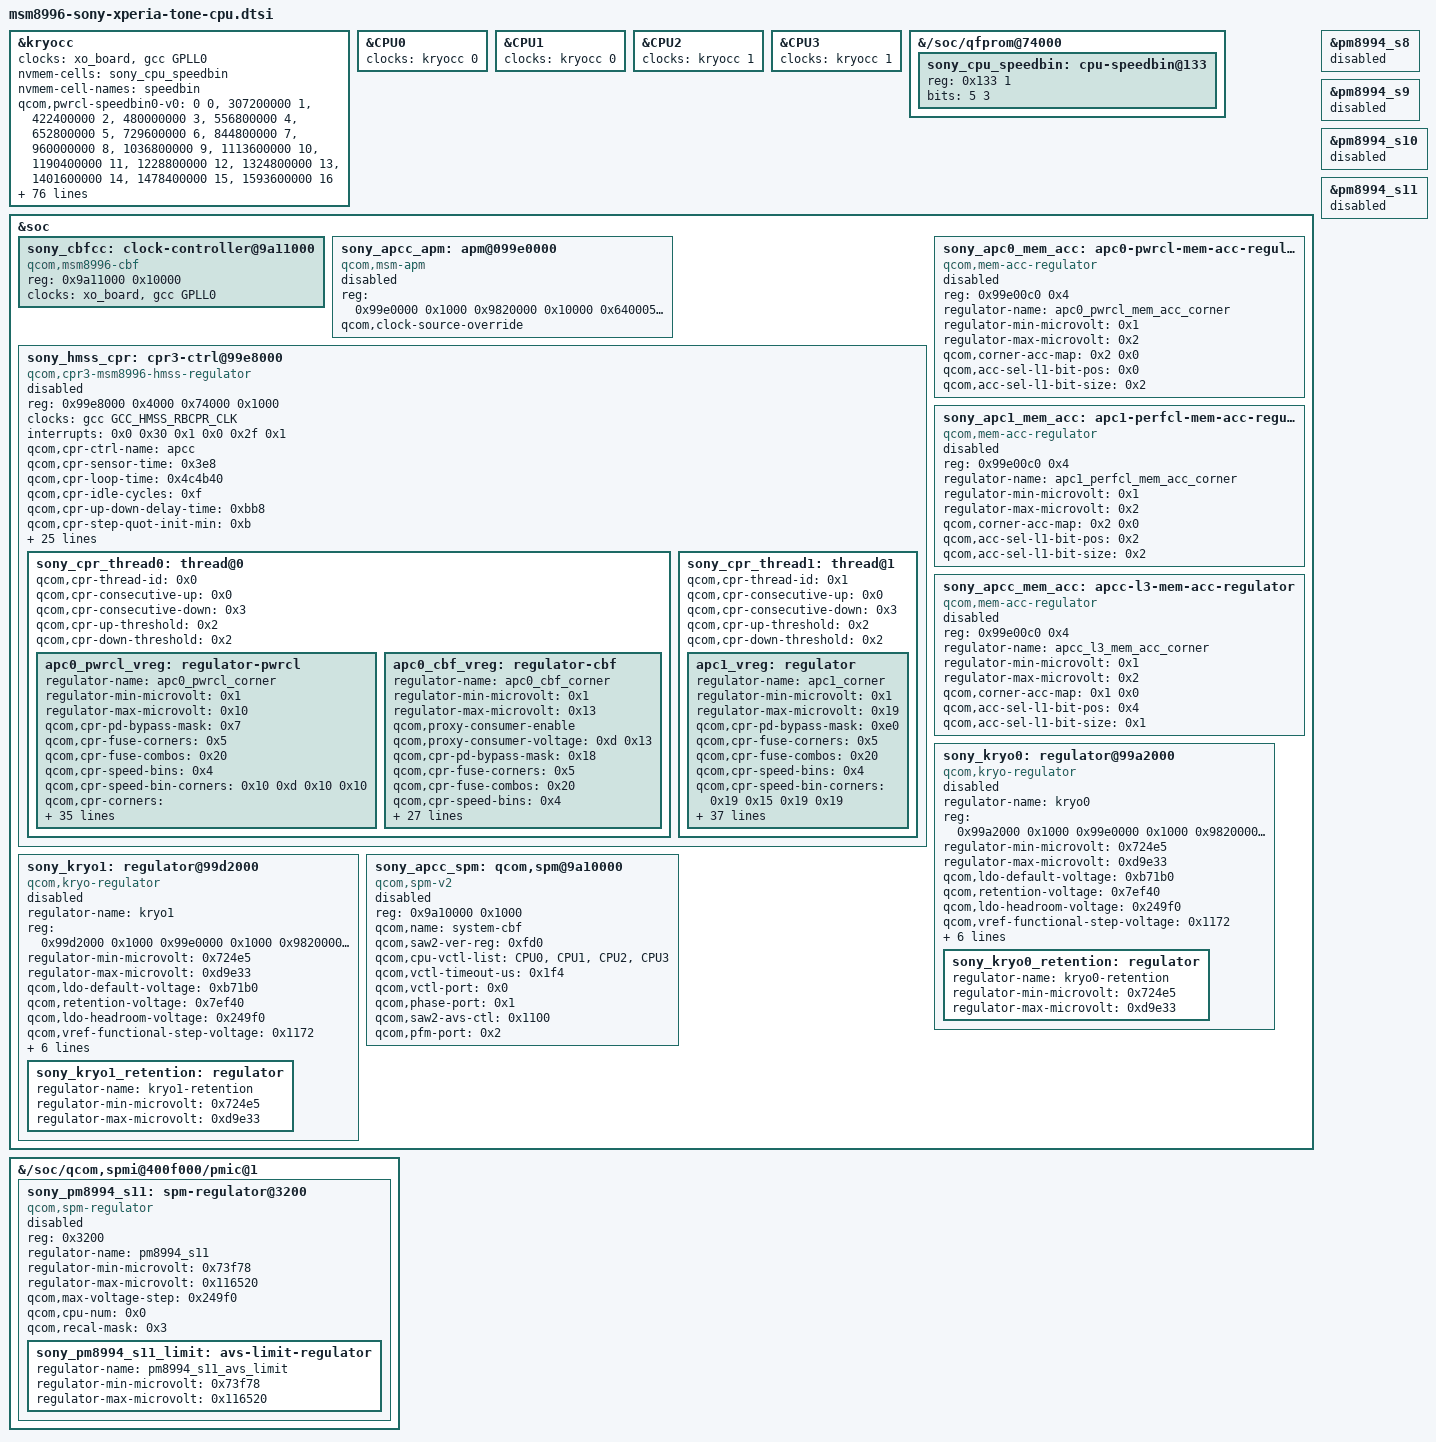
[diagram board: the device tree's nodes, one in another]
// SPDX-License-Identifier: GPL-2.0-only
/*
 * Copyright (c) 2014-2018, The Linux Foundation. All rights reserved.
 *
 * CPU/CBF data from the FINAL flattened Sony Dora v3.1/PMI8994 DT at
 * 0c295b15b6d0fb59a64e13b9e0ef2070818ef2a1, including all overrides.
 * APCC/CBF providers only observe firmware rates. All voltage controllers
 * below remain DISABLED: ACD/CPR transitions and RPM corner voting have not
 * been validated. Do not enable cpufreq, cpuidle or remove maxcpus=2 here.
 */

&kryocc {
	/* Sony sys_apcsaux_clk is GPLL0 main output divided by two. */
	clocks = <&xo_board>, <&gcc GPLL0>;
	clock-names = "xo", "aux";
	nvmem-cells = <&sony_cpu_speedbin>;
	nvmem-cell-names = "speedbin";
	qcom,pwrcl-speedbin0-v0 =
		<0 0>,
		<307200000 1>,
		<422400000 2>,
		<480000000 3>,
		<556800000 4>,
		<652800000 5>,
		<729600000 6>,
		<844800000 7>,
		<960000000 8>,
		<1036800000 9>,
		<1113600000 10>,
		<1190400000 11>,
		<1228800000 12>,
		<1324800000 13>,
		<1401600000 14>,
		<1478400000 15>,
		<1593600000 16>;
	qcom,perfcl-speedbin0-v0 =
		<0 0>,
		<307200000 1>,
		<403200000 2>,
		<480000000 3>,
		<556800000 4>,
		<652800000 5>,
		<729600000 6>,
		<806400000 7>,
		<883200000 8>,
		<940800000 9>,
		<1036800000 10>,
		<1113600000 11>,
		<1190400000 12>,
		<1248000000 13>,
		<1324800000 14>,
		<1401600000 15>,
		<1478400000 16>,
		<1555200000 17>,
		<1632000000 18>,
		<1708800000 19>,
		<1785600000 20>,
		<1824000000 21>,
		<1920000000 22>,
		<1996800000 23>,
		<2073600000 24>,
		<2150400000 25>;
	qcom,cbf-speedbin0-v0 =
		<0 0>,
		<307200000 1>,
		<384000000 2>,
		<460800000 3>,
		<537600000 4>,
		<595200000 5>,
		<672000000 6>,
		<748800000 7>,
		<825600000 8>,
		<902400000 9>,
		<979200000 10>,
		<1056000000 11>,
		<1132800000 12>,
		<1190400000 13>,
		<1228800000 14>,
		<1305600000 15>,
		<1382400000 16>,
		<1459200000 17>,
		<1536000000 18>,
		<1593600000 19>;
	qcom,pwrcl-speedbin1-v0 =
		<0 0>,
		<307200000 1>,
		<422400000 2>,
		<480000000 3>,
		<556800000 4>,
		<652800000 5>,
		<729600000 6>,
		<844800000 7>,
		<960000000 8>,
		<1036800000 9>,
		<1113600000 10>,
		<1190400000 11>,
		<1228800000 12>,
		<1363200000 13>;
	qcom,pwrcl-speedbin2-v0 =
		<0 0>,
		<307200000 1>,
		<422400000 2>,
		<480000000 3>,
		<556800000 4>,
		<652800000 5>,
		<729600000 6>,
		<844800000 7>,
		<960000000 8>,
		<1036800000 9>,
		<1113600000 10>,
		<1190400000 11>,
		<1228800000 12>,
		<1324800000 13>,
		<1401600000 14>,
		<1497600000 15>;
	qcom,pwrcl-speedbin3-v0 =
		<0 0>,
		<307200000 1>,
		<422400000 2>,
		<480000000 3>,
		<556800000 4>,
		<652800000 5>,
		<729600000 6>,
		<844800000 7>,
		<960000000 8>,
		<1036800000 9>,
		<1113600000 10>,
		<1190400000 11>,
		<1228800000 12>,
		<1324800000 13>,
		<1401600000 14>,
		<1478400000 15>,
		<1593600000 16>;
	qcom,perfcl-speedbin1-v0 =
		<0 0>,
		<307200000 1>,
		<403200000 2>,
		<480000000 3>,
		<556800000 4>,
		<652800000 5>,
		<729600000 6>,
		<806400000 7>,
		<883200000 8>,
		<940800000 9>,
		<1036800000 10>,
		<1113600000 11>,
		<1190400000 12>,
		<1248000000 13>,
		<1324800000 14>,
		<1401600000 15>,
		<1478400000 16>,
		<1555200000 17>,
		<1632000000 18>,
		<1708800000 19>,
		<1785600000 20>,
		<1804800000 21>;
	qcom,perfcl-speedbin2-v0 =
		<0 0>,
		<307200000 1>,
		<403200000 2>,
		<480000000 3>,
		<556800000 4>,
		<652800000 5>,
		<729600000 6>,
		<806400000 7>,
		<883200000 8>,
		<940800000 9>,
		<1036800000 10>,
		<1113600000 11>,
		<1190400000 12>,
		<1248000000 13>,
		<1324800000 14>,
		<1401600000 15>,
		<1478400000 16>,
		<1555200000 17>,
		<1632000000 18>,
		<1708800000 19>,
		<1785600000 20>,
		<1804800000 21>,
		<1900800000 22>;
	qcom,perfcl-speedbin3-v0 =
		<0 0>,
		<307200000 1>,
		<403200000 2>,
		<480000000 3>,
		<556800000 4>,
		<652800000 5>,
		<729600000 6>,
		<806400000 7>,
		<883200000 8>,
		<940800000 9>,
		<1036800000 10>,
		<1113600000 11>,
		<1190400000 12>,
		<1248000000 13>,
		<1324800000 14>,
		<1401600000 15>,
		<1478400000 16>,
		<1555200000 17>,
		<1632000000 18>,
		<1708800000 19>,
		<1785600000 20>,
		<1804800000 21>;
	qcom,cbf-speedbin1-v0 =
		<0 0>,
		<307200000 1>,
		<384000000 2>,
		<460800000 3>,
		<537600000 4>,
		<595200000 5>,
		<672000000 6>,
		<748800000 7>,
		<825600000 8>,
		<902400000 9>,
		<979200000 10>,
		<1056000000 11>,
		<1132800000 12>,
		<1190400000 13>,
		<1228800000 14>,
		<1305600000 15>;
	qcom,cbf-speedbin2-v0 =
		<0 0>,
		<307200000 1>,
		<384000000 2>,
		<460800000 3>,
		<537600000 4>,
		<595200000 5>,
		<672000000 6>,
		<748800000 7>,
		<825600000 8>,
		<902400000 9>,
		<979200000 10>,
		<1056000000 11>,
		<1132800000 12>,
		<1190400000 13>,
		<1228800000 14>,
		<1305600000 15>;
	qcom,cbf-speedbin3-v0 =
		<0 0>,
		<307200000 1>,
		<384000000 2>,
		<460800000 3>,
		<537600000 4>,
		<595200000 5>,
		<672000000 6>,
		<748800000 7>,
		<825600000 8>,
		<902400000 9>,
		<979200000 10>,
		<1056000000 11>,
		<1132800000 12>,
		<1190400000 13>,
		<1228800000 14>,
		<1305600000 15>,
		<1382400000 16>,
		<1459200000 17>,
		<1536000000 18>,
		<1593600000 19>;
};

&CPU0 { clocks = <&kryocc 0>; };
&CPU1 { clocks = <&kryocc 0>; };
&CPU2 { clocks = <&kryocc 1>; };
&CPU3 { clocks = <&kryocc 1>; };

&{/soc/qfprom@74000} {
	/* NVMEM bit offsets are byte-relative (0..7). Sony EFUSE[31:29]. */
	sony_cpu_speedbin: cpu-speedbin@133 {
		reg = <0x133 1>;
		bits = <5 3>;
	};
};

&soc {
	sony_cbfcc: clock-controller@9a11000 {
		compatible = "qcom,msm8996-cbf";
		reg = <0x9a11000 0x10000>;
		#clock-cells = <1>;
		clocks = <&xo_board>, <&gcc GPLL0>;
		clock-names = "xo", "aux";
	};
	sony_apcc_apm: apm@099e0000 {
		status = "disabled";
		compatible = "qcom,msm-apm";
		reg = <0x99e0000 0x1000 0x9820000 0x10000 0x6400050 0x8
			0x6480050 0x8 0x9981068 0x8 0x9991068 0x8
			0x99b1068 0x8 0x99c1068 0x8 0x99a1068 0x8
			0x99d1068 0x8>;
		reg-names = "pm-apcc-glb", "apcs-csr", "apc0-pll-ctl", "apc1-pll-ctl", "apc0-cpu0-spm", "apc0-cpu1-spm", "apc1-cpu0-spm", "apc1-cpu1-spm", "apc0-l2-spm", "apc1-l2-spm";
		qcom,clock-source-override;
	};
	sony_hmss_cpr: cpr3-ctrl@99e8000 {
		status = "disabled";
		compatible = "qcom,cpr3-msm8996-hmss-regulator";
		reg = <0x99e8000 0x4000 0x74000 0x1000>;
		reg-names = "cpr_ctrl", "fuse_base";
		clocks = <&gcc GCC_HMSS_RBCPR_CLK>;
		clock-names = "core_clk";
		interrupts = <0x0 0x30 0x1 0x0 0x2f 0x1>;
		interrupt-names = "cpr", "ceiling";
		qcom,cpr-ctrl-name = "apcc";
		qcom,cpr-sensor-time = <0x3e8>;
		qcom,cpr-loop-time = <0x4c4b40>;
		qcom,cpr-idle-cycles = <0xf>;
		qcom,cpr-up-down-delay-time = <0xbb8>;
		qcom,cpr-step-quot-init-min = <0xb>;
		qcom,cpr-step-quot-init-max = <0xd>;
		qcom,cpr-count-mode = <0x0>;
		qcom,cpr-count-repeat = <0x19>;
		qcom,apm-ctrl = <&sony_apcc_apm>;
		qcom,apm-threshold-voltage = <0xcf850>;
		qcom,apm-hysteresis-voltage = <0x1388>;
		qcom,system-supply-max-voltage = <0xf7cd8>;
		qcom,mem-acc-supply-threshold-voltage = <0xaae60>;
		qcom,mem-acc-supply-corner-map = <0x1 0x2>;
		vdd-supply = <&sony_pm8994_s11>;
		qcom,voltage-step = <0x1388>;
		vdd-limit-supply = <&sony_pm8994_s11_limit>;
		mem-acc-thread0-supply = <&sony_apc0_mem_acc>;
		mem-acc-thread1-supply = <&sony_apc1_mem_acc>;
		mem-acc-supply = <&sony_apcc_mem_acc>;
		vdd-thread0-ldo-supply = <&sony_kryo0>;
		vdd-thread1-ldo-supply = <&sony_kryo1>;
		vdd-thread0-ldo-ret-supply = <&sony_kryo0_retention>;
		vdd-thread1-ldo-ret-supply = <&sony_kryo1_retention>;
		proxy-supply = <&apc0_cbf_vreg>;
		qcom,cpr-enable;
		qcom,cpr-clock-throttling = <0x20>;
		qcom,cpr-aging-ref-voltage = <0xdcf28>;
		sony_cpr_thread0: thread@0 {
			qcom,cpr-thread-id = <0x0>;
			qcom,cpr-consecutive-up = <0x0>;
			qcom,cpr-consecutive-down = <0x3>;
			qcom,cpr-up-threshold = <0x2>;
			qcom,cpr-down-threshold = <0x2>;
			apc0_pwrcl_vreg: regulator-pwrcl {
				regulator-name = "apc0_pwrcl_corner";
				regulator-min-microvolt = <0x1>;
				regulator-max-microvolt = <0x10>;
				qcom,cpr-pd-bypass-mask = <0x7>;
				qcom,cpr-fuse-corners = <0x5>;
				qcom,cpr-fuse-combos = <0x20>;
				qcom,cpr-speed-bins = <0x4>;
				qcom,cpr-speed-bin-corners = <0x10 0xd 0x10 0x10>;
				qcom,cpr-corners = <0x10 0x10 0x10 0x10 0x10 0x10
					0x10 0x10 0xd 0xd 0xd 0xd
					0xd 0xd 0xd 0xd 0x10 0x10
					0x10 0x10 0x10 0x10 0x10 0x10
					0x10 0x10 0x10 0x10 0x10 0x10
					0x10 0x10>;
				qcom,ldo-min-headroom-voltage = <0x249f0>;
				qcom,ldo-max-headroom-voltage = <0x72bf0>;
				qcom,ldo-max-voltage = <0xd9490>;
				qcom,uses-mem-acc;
				qcom,cpr-corner-fmax-map = <0x1 0x2 0x7 0xc 0x10 0x1
					0x2 0x7 0xc 0xd 0x1 0x2
					0x7 0xc 0x10 0x1 0x2 0x7
					0xc 0x10>;
				qcom,cpr-voltage-ceiling = <0xa3930 0xa3930 0xb5e28 0xb5e28 0xb5e28 0xb5e28
					0xb5e28 0xdcf28 0xdcf28 0xdcf28 0xdcf28 0xdcf28
					0x116520 0x116520 0x116520 0x116520 0xa3930 0xa3930
					0xb5e28 0xb5e28 0xb5e28 0xb5e28 0xb5e28 0xdcf28
					0xdcf28 0xdcf28 0xdcf28 0xdcf28 0x116520 0xa3930
					0xa3930 0xb5e28 0xb5e28 0xb5e28 0xb5e28 0xb5e28
					0xdcf28 0xdcf28 0xdcf28 0xdcf28 0xdcf28 0x116520
					0x116520 0x116520 0x116520 0xa3930 0xa3930 0xb5e28
					0xb5e28 0xb5e28 0xb5e28 0xb5e28 0xdcf28 0xdcf28
					0xdcf28 0xdcf28 0xdcf28 0x116520 0x116520 0x116520
					0x116520>;
				qcom,cpr-voltage-floor = <0x98968 0x98968 0x98968 0x98968 0x98968 0x98968
					0x98968 0x98968 0x98968 0x98968 0x98968 0x98968
					0x98968 0x98968 0x98968 0x98968 0x98968 0x98968
					0x98968 0x98968 0x98968 0x98968 0x98968 0x98968
					0x98968 0x98968 0x98968 0x98968 0x98968 0x98968
					0x98968 0x98968 0x98968 0x98968 0x98968 0x98968
					0x98968 0x98968 0x98968 0x98968 0x98968 0x98968
					0x98968 0x98968 0x98968 0x98968 0x98968 0x98968
					0x98968 0x98968 0x98968 0x98968 0x98968 0x98968
					0x98968 0x98968 0x98968 0x98968 0x98968 0x98968
					0x98968 0x98968 0x98968 0x98968 0x98968 0x98968
					0x98968 0x98968 0x98968 0x98968 0x98968 0x98968
					0x98968 0x98968 0x98968 0x98968 0x98968 0x98968
					0x98968 0x98968 0x98968 0x98968 0x98968 0x98968
					0x98968 0x98968 0x98968 0x98968 0x98968 0x98968
					0x98968 0x98968 0x98968 0x98968 0x98968 0x98968
					0x72bf0 0x72bf0 0x72bf0 0x72bf0 0x72bf0 0x72bf0
					0x72bf0 0x72bf0 0x72bf0 0x72bf0 0x72bf0 0x72bf0
					0x72bf0 0x72bf0 0x72bf0 0x72bf0 0x72bf0 0x72bf0
					0x72bf0 0x72bf0 0x72bf0 0x72bf0 0x72bf0 0x72bf0
					0x72bf0 0x72bf0 0x72bf0 0x72bf0 0x72bf0 0x72bf0
					0x72bf0 0x72bf0 0x98968 0x98968 0x98968 0x98968
					0x98968 0x98968 0x98968 0x98968 0x98968 0x98968
					0x98968 0x98968 0x98968 0x98968 0x98968 0x98968
					0x98968 0x98968 0x98968 0x98968 0x98968 0x98968
					0x98968 0x98968 0x98968 0x98968 0x98968 0x98968
					0x98968 0x98968 0x98968 0x98968 0x98968 0x98968
					0x98968 0x98968 0x98968 0x98968 0x98968 0x98968
					0x98968 0x98968 0x98968 0x98968 0x98968 0x98968
					0x98968 0x98968 0x98968 0x98968 0x98968 0x98968
					0x98968 0x98968 0x98968 0x98968 0x98968 0x98968
					0x98968 0x98968 0x98968 0x98968 0x98968 0x98968
					0x98968 0x98968 0x98968 0x98968 0x98968 0x98968
					0x98968 0x98968 0x98968 0x98968 0x98968 0x98968
					0x98968 0x98968 0x72bf0 0x72bf0 0x72bf0 0x72bf0
					0x72bf0 0x72bf0 0x72bf0 0x72bf0 0x72bf0 0x72bf0
					0x72bf0 0x72bf0 0x72bf0 0x72bf0 0x72bf0 0x72bf0
					0x72bf0 0x72bf0 0x72bf0 0x72bf0 0x72bf0 0x72bf0
					0x72bf0 0x72bf0 0x72bf0 0x72bf0 0x98968 0x98968
					0x98968 0x98968 0x98968 0x98968 0x98968 0x98968
					0x98968 0x98968 0x98968 0x98968 0x98968 0x98968
					0x98968 0x98968 0x98968 0x98968 0x98968 0x98968
					0x98968 0x98968 0x98968 0x98968 0x98968 0x98968
					0x98968 0x98968 0x98968 0x98968 0x98968 0x98968
					0x98968 0x98968 0x98968 0x98968 0x98968 0x98968
					0x98968 0x98968 0x98968 0x98968 0x98968 0x98968
					0x98968 0x98968 0x98968 0x98968 0x98968 0x98968
					0x98968 0x98968 0x98968 0x98968 0x98968 0x98968
					0x98968 0x98968 0x98968 0x98968 0x98968 0x98968
					0x98968 0x98968 0x98968 0x98968 0x98968 0x98968
					0x98968 0x98968 0x98968 0x98968 0x98968 0x98968
					0x98968 0x98968 0x98968 0x98968 0x98968 0x98968
					0x98968 0x98968 0x98968 0x98968 0x98968 0x98968
					0x98968 0x98968 0x98968 0x98968 0x98968 0x98968
					0x98968 0x98968 0x98968 0x98968 0x72bf0 0x72bf0
					0x72bf0 0x72bf0 0x72bf0 0x72bf0 0x72bf0 0x72bf0
					0x72bf0 0x72bf0 0x72bf0 0x72bf0 0x72bf0 0x72bf0
					0x72bf0 0x72bf0 0x72bf0 0x72bf0 0x72bf0 0x72bf0
					0x72bf0 0x72bf0 0x72bf0 0x72bf0 0x72bf0 0x72bf0
					0x72bf0 0x72bf0 0x72bf0 0x72bf0 0x72bf0 0x72bf0
					0x98968 0x98968 0x98968 0x98968 0x98968 0x98968
					0x98968 0x98968 0x98968 0x98968 0x98968 0x98968
					0x98968 0x98968 0x98968 0x98968 0x98968 0x98968
					0x98968 0x98968 0x98968 0x98968 0x98968 0x98968
					0x98968 0x98968 0x98968 0x98968 0x98968 0x98968
					0x98968 0x98968 0x98968 0x98968 0x98968 0x98968
					0x98968 0x98968 0x98968 0x98968 0x98968 0x98968
					0x98968 0x98968 0x98968 0x98968 0x98968 0x98968
					0x98968 0x98968 0x98968 0x98968 0x98968 0x98968
					0x98968 0x98968 0x98968 0x98968 0x98968 0x98968
					0x98968 0x98968 0x98968 0x98968 0x98968 0x98968
					0x98968 0x98968 0x98968 0x98968 0x98968 0x98968
					0x98968 0x98968 0x98968 0x98968 0x98968 0x98968
					0x98968 0x98968 0x98968 0x98968 0x98968 0x98968
					0x98968 0x98968 0x98968 0x98968 0x98968 0x98968
					0x98968 0x98968 0x98968 0x98968 0x98968 0x98968
					0x72bf0 0x72bf0 0x72bf0 0x72bf0 0x72bf0 0x72bf0
					0x72bf0 0x72bf0 0x72bf0 0x72bf0 0x72bf0 0x72bf0
					0x72bf0 0x72bf0 0x72bf0 0x72bf0 0x72bf0 0x72bf0
					0x72bf0 0x72bf0 0x72bf0 0x72bf0 0x72bf0 0x72bf0
					0x72bf0 0x72bf0 0x72bf0 0x72bf0 0x72bf0 0x72bf0
					0x72bf0 0x72bf0>;
				qcom,cpr-floor-to-ceiling-max-range = <0xc350 0xc350 0x13880 0x13880 0x13880 0x13880
					0x13880 0x13880 0x13880 0x13880 0x13880 0x13880
					0x13880 0x13880 0x13880 0x13880 0xc350 0xc350
					0x13880 0x13880 0x13880 0x13880 0x13880 0x13880
					0x13880 0x13880 0x13880 0x13880 0x13880 0xc350
					0xc350 0x13880 0x13880 0x13880 0x13880 0x13880
					0x13880 0x13880 0x13880 0x13880 0x13880 0x13880
					0x13880 0x13880 0x13880 0xc350 0xc350 0x13880
					0x13880 0x13880 0x13880 0x13880 0x13880 0x13880
					0x13880 0x13880 0x13880 0x13880 0x13880 0x13880
					0x13880>;
				qcom,corner-frequencies = <0x124f8000 0x192d5000 0x1c9c3800 0x21301800 0x26e8f000 0x2b7cd000
					0x325aa000 0x39387000 0x3dcc5000 0x42603000 0x46f41000 0x493e0000
					0x4ef6d800 0x538ab800 0x581e9800 0x5efc6800 0x124f8000 0x192d5000
					0x1c9c3800 0x21301800 0x26e8f000 0x2b7cd000 0x325aa000 0x39387000
					0x3dcc5000 0x42603000 0x46f41000 0x493e0000 0x5140c800 0x124f8000
					0x192d5000 0x1c9c3800 0x21301800 0x26e8f000 0x2b7cd000 0x325aa000
					0x39387000 0x3dcc5000 0x42603000 0x46f41000 0x493e0000 0x4ef6d800
					0x538ab800 0x581e9800 0x5efc6800 0x124f8000 0x192d5000 0x1c9c3800
					0x21301800 0x26e8f000 0x2b7cd000 0x325aa000 0x39387000 0x3dcc5000
					0x42603000 0x46f41000 0x493e0000 0x4ef6d800 0x538ab800 0x581e9800
					0x5efc6800>;
				qcom,cpr-ro-scaling-factor = <0x0 0x0 0xc28 0xa6a 0xb83 0x9ef
					0x8df 0x7bb 0xa3f 0x90d 0xad4 0x992
					0x0 0x0 0x0 0x0 0x0 0x0
					0xc28 0xa6a 0xb83 0x9ef 0x8df 0x7bb
					0xa3f 0x90d 0xad4 0x992 0x0 0x0
					0x0 0x0 0x0 0x0 0xc28 0xa6a
					0xb83 0x9ef 0x8df 0x7bb 0xa3f 0x90d
					0xad4 0x992 0x0 0x0 0x0 0x0
					0x0 0x0 0xc28 0xa6a 0xb83 0x9ef
					0x8df 0x7bb 0xa3f 0x90d 0xad4 0x992
					0x0 0x0 0x0 0x0 0x0 0x0
					0xb49 0x9e0 0xab4 0x97a 0x906 0x7f8
					0x9d7 0x8d1 0xa6c 0x944 0x0 0x0
					0x0 0x0>;
				qcom,cpr-open-loop-voltage-fuse-adjustment = <0x9c40 0x4e20 0xafc8 0x3a98 0x2710 0x9c40
					0x4e20 0xafc8 0x3a98 0x2710 0x9c40 0x4e20
					0xafc8 0x3a98 0x2710 0xd6d8 0x4e20 0xea60
					0x7530 0x61a8 0xd6d8 0x4e20 0xea60 0x7530
					0x61a8 0xd6d8 0x4e20 0xea60 0x7530 0x61a8
					0xd6d8 0x4e20 0xea60 0x7530 0x61a8 0xd6d8
					0x4e20 0xea60 0x7530 0x61a8 0x9c40 0x4e20
					0xafc8 0x3a98 0x2710 0x9c40 0x4e20 0xafc8
					0x3a98 0x2710 0x9c40 0x4e20 0xafc8 0x3a98
					0x2710 0xd6d8 0x4e20 0xea60 0x7530 0x61a8
					0xd6d8 0x4e20 0xea60 0x7530 0x61a8 0xd6d8
					0x4e20 0xea60 0x7530 0x61a8 0xd6d8 0x4e20
					0xea60 0x7530 0x61a8 0xd6d8 0x4e20 0xea60
					0x7530 0x61a8 0x4e20 0x0 0x61a8 0xffffec78
					0xffffd8f0 0x4e20 0x0 0x61a8 0xffffec78 0xffffd8f0
					0x4e20 0x0 0x61a8 0xffffec78 0xffffd8f0 0x88b8
					0x0 0x9c40 0x2710 0x1388 0x88b8 0x0
					0x9c40 0x2710 0x1388 0x88b8 0x0 0x9c40
					0x2710 0x1388 0x88b8 0x0 0x9c40 0x2710
					0x1388 0x88b8 0x0 0x9c40 0x2710 0x1388
					0x4e20 0x0 0x61a8 0xffffec78 0xffffd8f0 0x4e20
					0x0 0x61a8 0xffffec78 0xffffd8f0 0x4e20 0x0
					0x61a8 0xffffec78 0xffffd8f0 0x88b8 0x0 0x9c40
					0x2710 0x1388 0x88b8 0x0 0x9c40 0x2710
					0x1388 0x88b8 0x0 0x9c40 0x2710 0x1388
					0x88b8 0x0 0x9c40 0x2710 0x1388 0x88b8
					0x0 0x9c40 0x2710 0x1388>;
				qcom,cpr-closed-loop-voltage-fuse-adjustment = <0xd6d8 0xd6d8 0xea60 0xea60 0xea60 0x9c40
					0x7530 0x61a8 0x3a98 0x3a98 0x9c40 0x7530
					0x61a8 0x3a98 0x3a98 0x9c40 0x7530 0x61a8
					0x3a98 0x3a98 0x9c40 0x7530 0x61a8 0x3a98
					0x3a98 0x9c40 0x7530 0x61a8 0x3a98 0x3a98
					0x9c40 0x7530 0x61a8 0x3a98 0x3a98 0x9c40
					0x7530 0x61a8 0x3a98 0x3a98 0xd6d8 0xd6d8
					0xea60 0xea60 0xea60 0x9c40 0x7530 0x61a8
					0x3a98 0x3a98 0x9c40 0x7530 0x61a8 0x3a98
					0x3a98 0x9c40 0x7530 0x61a8 0x3a98 0x3a98
					0x9c40 0x7530 0x61a8 0x3a98 0x3a98 0x9c40
					0x7530 0x61a8 0x3a98 0x3a98 0x9c40 0x7530
					0x61a8 0x3a98 0x3a98 0x9c40 0x7530 0x61a8
					0x3a98 0x3a98 0x88b8 0x88b8 0x9c40 0x9c40
					0x9c40 0x4e20 0x2710 0x1388 0xffffec78 0xffffec78
					0x4e20 0x2710 0x1388 0xffffec78 0xffffec78 0x4e20
					0x2710 0x1388 0xffffec78 0xffffec78 0x4e20 0x2710
					0x1388 0xffffec78 0xffffec78 0x4e20 0x2710 0x1388
					0xffffec78 0xffffec78 0x4e20 0x2710 0x1388 0xffffec78
					0xffffec78 0x4e20 0x2710 0x1388 0xffffec78 0xffffec78
					0x88b8 0x88b8 0x9c40 0x9c40 0x9c40 0x4e20
					0x2710 0x1388 0xffffec78 0xffffec78 0x4e20 0x2710
					0x1388 0xffffec78 0xffffec78 0x4e20 0x2710 0x1388
					0xffffec78 0xffffec78 0x4e20 0x2710 0x1388 0xffffec78
					0xffffec78 0x4e20 0x2710 0x1388 0xffffec78 0xffffec78
					0x4e20 0x2710 0x1388 0xffffec78 0xffffec78 0x4e20
					0x2710 0x1388 0xffffec78 0xffffec78>;
				qcom,cpr-open-loop-voltage-adjustment = <0xffffc568 0xffffc568 0xffffc568 0xffffc568 0xffffcd38 0xffffc950
					0xffffc568 0xffffb9b0 0xffffb1e0 0xffffaa10 0xffffa240 0xffff9e58
					0xffff9a70 0xffff9688 0xffff92a0 0xffff8ad0 0xffffc568 0xffffc568
					0xffffc568 0xffffc568 0xffffcd38 0xffffc950 0xffffc568 0xffffb9b0
					0xffffb1e0 0xffffaa10 0xffffa240 0xffff9e58 0xffff9a70 0xffffc568
					0xffffc568 0xffffc568 0xffffc568 0xffffcd38 0xffffc950 0xffffc568
					0xffffb9b0 0xffffb1e0 0xffffaa10 0xffffa240 0xffff9e58 0xffff9a70
					0xffff9688 0xffff92a0 0xffff8ad0 0xffffc568 0xffffc568 0xffffc568
					0xffffc568 0xffffcd38 0xffffc950 0xffffc568 0xffffb9b0 0xffffb1e0
					0xffffaa10 0xffffa240 0xffff9e58 0xffff9a70 0xffff9688 0xffff92a0
					0xffff8ad0>;
				qcom,cpr-open-loop-voltage-min-diff = <0x0 0x0 0x0 0x0 0xffff3cb0 0x0
					0x0 0x0 0x0 0x0 0x0 0x0
					0x0 0x0 0x0 0x0 0x0 0x0
					0x0 0x0 0xffff3cb0 0x0 0x0 0x0
					0x0 0x0 0x0 0x0 0x0 0x0
					0x0 0x0 0x0 0xffff3cb0 0x0 0x0
					0x0 0x0 0x0 0x0 0x0 0x0
					0x0 0x0 0x0 0x0 0x0 0x0
					0x0 0xffff3cb0 0x0 0x0 0x0 0x0
					0x0 0x0 0x0 0x0 0x0 0x0
					0x0>;
				qcom,cpr-closed-loop-voltage-adjustment = <0xffffc568 0xffffc568 0xffffc568 0xffffc568 0xffffcd38 0xffffc950
					0xffffc568 0xffffb9b0 0xffffb1e0 0xffffaa10 0xffffa240 0xffff9e58
					0xffff9a70 0xffff9688 0xffff92a0 0xffff8ad0 0xffffc568 0xffffc568
					0xffffc568 0xffffc568 0xffffcd38 0xffffc950 0xffffc568 0xffffb9b0
					0xffffb1e0 0xffffaa10 0xffffa240 0xffff9e58 0xffff9a70 0xffffc568
					0xffffc568 0xffffc568 0xffffc568 0xffffcd38 0xffffc950 0xffffc568
					0xffffb9b0 0xffffb1e0 0xffffaa10 0xffffa240 0xffff9e58 0xffff9a70
					0xffff9688 0xffff92a0 0xffff8ad0 0xffffc568 0xffffc568 0xffffc568
					0xffffc568 0xffffcd38 0xffffc950 0xffffc568 0xffffb9b0 0xffffb1e0
					0xffffaa10 0xffffa240 0xffff9e58 0xffff9a70 0xffff9688 0xffff92a0
					0xffff8ad0>;
				qcom,allow-voltage-interpolation;
				qcom,allow-quotient-interpolation;
				qcom,cpr-scaled-open-loop-voltage-as-ceiling;
				qcom,cpr-aging-max-voltage-adjustment = <0x3a98>;
				qcom,cpr-aging-ref-corner = <0xc 0xc 0xc 0xc>;
				qcom,cpr-aging-ro-scaling-factor = <0xc80>;
				qcom,allow-aging-voltage-adjustment = <0x0 0x0 0x0 0x1 0x1 0x1
					0x1 0x1 0x0 0x0 0x0 0x1
					0x1 0x1 0x1 0x1 0x0 0x0
					0x0 0x1 0x1 0x1 0x1 0x1
					0x0 0x0 0x0 0x1 0x1 0x1
					0x1 0x1>;
			};
			apc0_cbf_vreg: regulator-cbf {
				regulator-name = "apc0_cbf_corner";
				regulator-min-microvolt = <0x1>;
				regulator-max-microvolt = <0x13>;
				qcom,proxy-consumer-enable;
				qcom,proxy-consumer-voltage = <0xd 0x13>;
				qcom,cpr-pd-bypass-mask = <0x18>;
				qcom,cpr-fuse-corners = <0x5>;
				qcom,cpr-fuse-combos = <0x20>;
				qcom,cpr-speed-bins = <0x4>;
				qcom,cpr-speed-bin-corners = <0x13 0xf 0x13 0x13>;
				qcom,cpr-corners = <0x13 0x13 0x13 0x13 0x13 0x13
					0x13 0x13 0xf 0xf 0xf 0xf
					0xf 0xf 0xf 0xf 0x13 0x13
					0x13 0x13 0x13 0x13 0x13 0x13
					0x13 0x13 0x13 0x13 0x13 0x13
					0x13 0x13>;
				qcom,cpr-corner-fmax-map = <0x1 0x2 0x5 0xd 0x13 0x1
					0x2 0x5 0xd 0xf 0x1 0x2
					0x5 0xd 0x13 0x1 0x2 0x5
					0xd 0x13>;
				qcom,cpr-voltage-ceiling = <0xa3930 0xa3930 0xb5e28 0xb5e28 0xb5e28 0xdcf28
					0xdcf28 0xdcf28 0xdcf28 0xdcf28 0xdcf28 0xdcf28
					0xdcf28 0x116520 0x116520 0x116520 0x116520 0x116520
					0x116520 0xa3930 0xa3930 0xb5e28 0xb5e28 0xb5e28
					0xdcf28 0xdcf28 0xdcf28 0xdcf28 0xdcf28 0xdcf28
					0xdcf28 0xdcf28 0x116520 0x116520 0xa3930 0xa3930
					0xb5e28 0xb5e28 0xb5e28 0xdcf28 0xdcf28 0xdcf28
					0xdcf28 0xdcf28 0xdcf28 0xdcf28 0xdcf28 0x116520
					0x116520 0x116520 0x116520 0x116520 0x116520 0xa3930
					0xa3930 0xb5e28 0xb5e28 0xb5e28 0xdcf28 0xdcf28
					0xdcf28 0xdcf28 0xdcf28 0xdcf28 0xdcf28 0xdcf28
					0x116520 0x116520 0x116520 0x116520 0x116520 0x116520>;
				qcom,cpr-voltage-floor = <0x98968 0x98968 0x98968 0x98968 0x98968 0x98968
					0x98968 0x98968 0x98968 0x98968 0x98968 0x98968
					0x98968 0x98968 0x98968 0x98968 0x98968 0x98968
					0x98968 0x98968 0x98968 0x98968 0x98968 0x98968
					0x98968 0x98968 0x98968 0x98968 0x98968 0x98968
					0x98968 0x98968 0x98968 0x98968 0x98968 0x98968
					0x98968 0x98968 0x98968 0x98968 0x98968 0x98968
					0x98968 0x98968 0x98968 0x98968 0x98968 0x98968
					0x98968 0x98968 0x98968 0x98968 0x98968 0x98968
					0x98968 0x98968 0x98968 0x98968 0x98968 0x98968
					0x98968 0x98968 0x98968 0x98968 0x98968 0x98968
					0x98968 0x98968 0x98968 0x98968 0x98968 0x98968
					0x98968 0x98968 0x98968 0x98968 0x98968 0x98968
					0x98968 0x98968 0x98968 0x98968 0x98968 0x98968
					0x98968 0x98968 0x98968 0x98968 0x98968 0x98968
					0x98968 0x98968 0x98968 0x98968 0x98968 0x98968
					0x98968 0x98968 0x98968 0x98968 0x98968 0x98968
					0x98968 0x98968 0x98968 0x98968 0x98968 0x98968
					0x98968 0x98968 0x98968 0x98968 0x98968 0x98968
					0x72bf0 0x72bf0 0x72bf0 0x72bf0 0x72bf0 0x72bf0
					0x72bf0 0x72bf0 0x72bf0 0x72bf0 0x72bf0 0x72bf0
					0x72bf0 0x72bf0 0x72bf0 0x72bf0 0x72bf0 0x72bf0
					0x72bf0 0x72bf0 0x72bf0 0x72bf0 0x72bf0 0x72bf0
					0x72bf0 0x72bf0 0x72bf0 0x72bf0 0x72bf0 0x72bf0
					0x72bf0 0x72bf0 0x72bf0 0x72bf0 0x72bf0 0x72bf0
					0x72bf0 0x72bf0 0x98968 0x98968 0x98968 0x98968
					0x98968 0x98968 0x98968 0x98968 0x98968 0x98968
					0x98968 0x98968 0x98968 0x98968 0x98968 0x98968
					0x98968 0x98968 0x98968 0x98968 0x98968 0x98968
					0x98968 0x98968 0x98968 0x98968 0x98968 0x98968
					0x98968 0x98968 0x98968 0x98968 0x98968 0x98968
					0x98968 0x98968 0x98968 0x98968 0x98968 0x98968
					0x98968 0x98968 0x98968 0x98968 0x98968 0x98968
					0x98968 0x98968 0x98968 0x98968 0x98968 0x98968
					0x98968 0x98968 0x98968 0x98968 0x98968 0x98968
					0x98968 0x98968 0x98968 0x98968 0x98968 0x98968
					0x98968 0x98968 0x98968 0x98968 0x98968 0x98968
					0x98968 0x98968 0x98968 0x98968 0x98968 0x98968
					0x98968 0x98968 0x98968 0x98968 0x98968 0x98968
					0x98968 0x98968 0x98968 0x98968 0x98968 0x98968
					0x98968 0x98968 0x72bf0 0x72bf0 0x72bf0 0x72bf0
					0x72bf0 0x72bf0 0x72bf0 0x72bf0 0x72bf0 0x72bf0
					0x72bf0 0x72bf0 0x72bf0 0x72bf0 0x72bf0 0x72bf0
					0x72bf0 0x72bf0 0x72bf0 0x72bf0 0x72bf0 0x72bf0
					0x72bf0 0x72bf0 0x72bf0 0x72bf0 0x72bf0 0x72bf0
					0x72bf0 0x72bf0 0x98968 0x98968 0x98968 0x98968
					0x98968 0x98968 0x98968 0x98968 0x98968 0x98968
					0x98968 0x98968 0x98968 0x98968 0x98968 0x98968
					0x98968 0x98968 0x98968 0x98968 0x98968 0x98968
					0x98968 0x98968 0x98968 0x98968 0x98968 0x98968
					0x98968 0x98968 0x98968 0x98968 0x98968 0x98968
					0x98968 0x98968 0x98968 0x98968 0x98968 0x98968
					0x98968 0x98968 0x98968 0x98968 0x98968 0x98968
					0x98968 0x98968 0x98968 0x98968 0x98968 0x98968
					0x98968 0x98968 0x98968 0x98968 0x98968 0x98968
					0x98968 0x98968 0x98968 0x98968 0x98968 0x98968
					0x98968 0x98968 0x98968 0x98968 0x98968 0x98968
					0x98968 0x98968 0x98968 0x98968 0x98968 0x98968
					0x98968 0x98968 0x98968 0x98968 0x98968 0x98968
					0x98968 0x98968 0x98968 0x98968 0x98968 0x98968
					0x98968 0x98968 0x98968 0x98968 0x98968 0x98968
					0x98968 0x98968 0x98968 0x98968 0x98968 0x98968
					0x98968 0x98968 0x98968 0x98968 0x98968 0x98968
					0x98968 0x98968 0x98968 0x98968 0x98968 0x98968
					0x98968 0x98968 0x72bf0 0x72bf0 0x72bf0 0x72bf0
					0x72bf0 0x72bf0 0x72bf0 0x72bf0 0x72bf0 0x72bf0
					0x72bf0 0x72bf0 0x72bf0 0x72bf0 0x72bf0 0x72bf0
					0x72bf0 0x72bf0 0x72bf0 0x72bf0 0x72bf0 0x72bf0
					0x72bf0 0x72bf0 0x72bf0 0x72bf0 0x72bf0 0x72bf0
					0x72bf0 0x72bf0 0x72bf0 0x72bf0 0x72bf0 0x72bf0
					0x72bf0 0x72bf0 0x72bf0 0x72bf0 0x98968 0x98968
					0x98968 0x98968 0x98968 0x98968 0x98968 0x98968
					0x98968 0x98968 0x98968 0x98968 0x98968 0x98968
					0x98968 0x98968 0x98968 0x98968 0x98968 0x98968
					0x98968 0x98968 0x98968 0x98968 0x98968 0x98968
					0x98968 0x98968 0x98968 0x98968 0x98968 0x98968
					0x98968 0x98968 0x98968 0x98968 0x98968 0x98968
					0x98968 0x98968 0x98968 0x98968 0x98968 0x98968
					0x98968 0x98968 0x98968 0x98968 0x98968 0x98968
					0x98968 0x98968 0x98968 0x98968 0x98968 0x98968
					0x98968 0x98968 0x98968 0x98968 0x98968 0x98968
					0x98968 0x98968 0x98968 0x98968 0x98968 0x98968
					0x98968 0x98968 0x98968 0x98968 0x98968 0x98968
					0x98968 0x98968 0x98968 0x98968 0x98968 0x98968
					0x98968 0x98968 0x98968 0x98968 0x98968 0x98968
					0x98968 0x98968 0x98968 0x98968 0x98968 0x98968
					0x98968 0x98968 0x98968 0x98968 0x98968 0x98968
					0x98968 0x98968 0x98968 0x98968 0x98968 0x98968
					0x98968 0x98968 0x98968 0x98968 0x98968 0x98968
					0x98968 0x98968 0x98968 0x98968 0x72bf0 0x72bf0
					0x72bf0 0x72bf0 0x72bf0 0x72bf0 0x72bf0 0x72bf0
					0x72bf0 0x72bf0 0x72bf0 0x72bf0 0x72bf0 0x72bf0
					0x72bf0 0x72bf0 0x72bf0 0x72bf0 0x72bf0 0x72bf0
					0x72bf0 0x72bf0 0x72bf0 0x72bf0 0x72bf0 0x72bf0
					0x72bf0 0x72bf0 0x72bf0 0x72bf0 0x72bf0 0x72bf0
					0x72bf0 0x72bf0 0x72bf0 0x72bf0 0x72bf0 0x72bf0>;
				qcom,cpr-floor-to-ceiling-max-range = <0xc350 0xc350 0x13880 0x13880 0x13880 0x13880
					0x13880 0x13880 0x13880 0x13880 0x13880 0x13880
					0x13880 0x13880 0x13880 0x13880 0x13880 0x13880
					0x13880 0xc350 0xc350 0x13880 0x13880 0x13880
					0x13880 0x13880 0x13880 0x13880 0x13880 0x13880
					0x13880 0x13880 0x13880 0x13880 0xc350 0xc350
					0x13880 0x13880 0x13880 0x13880 0x13880 0x13880
					0x13880 0x13880 0x13880 0x13880 0x13880 0x13880
					0x13880 0x13880 0x13880 0x13880 0x13880 0xc350
					0xc350 0x13880 0x13880 0x13880 0x13880 0x13880
					0x13880 0x13880 0x13880 0x13880 0x13880 0x13880
					0x13880 0x13880 0x13880 0x13880 0x13880 0x13880>;
				qcom,corner-frequencies = <0x124f8000 0x16e36000 0x1b774000 0x200b2000 0x237a0800 0x280de800
					0x2ca1c800 0x3135a800 0x35c98800 0x3a5d6800 0x3ef14800 0x43852800
					0x46f41000 0x493e0000 0x4dd1e000 0x5265c000 0x56f9a000 0x5b8d8000
					0x5efc6800 0x124f8000 0x16e36000 0x1b774000 0x200b2000 0x237a0800
					0x280de800 0x2ca1c800 0x3135a800 0x35c98800 0x3a5d6800 0x3ef14800
					0x43852800 0x46f41000 0x493e0000 0x4dd1e000 0x124f8000 0x16e36000
					0x1b774000 0x200b2000 0x237a0800 0x280de800 0x2ca1c800 0x3135a800
					0x35c98800 0x3a5d6800 0x3ef14800 0x43852800 0x46f41000 0x493e0000
					0x4dd1e000 0x5265c000 0x56f9a000 0x5b8d8000 0x5efc6800 0x124f8000
					0x16e36000 0x1b774000 0x200b2000 0x237a0800 0x280de800 0x2ca1c800
					0x3135a800 0x35c98800 0x3a5d6800 0x3ef14800 0x43852800 0x46f41000
					0x493e0000 0x4dd1e000 0x5265c000 0x56f9a000 0x5b8d8000 0x5efc6800>;
				qcom,cpr-ro-scaling-factor = <0x0 0x0 0xc28 0xa6a 0xb83 0x9ef
					0x8df 0x7bb 0xa3f 0x90d 0xad4 0x992
					0x0 0x0 0x0 0x0 0x0 0x0
					0xc28 0xa6a 0xb83 0x9ef 0x8df 0x7bb
					0xa3f 0x90d 0xad4 0x992 0x0 0x0
					0x0 0x0 0x0 0x0 0xc28 0xa6a
					0xb83 0x9ef 0x8df 0x7bb 0xa3f 0x90d
					0xad4 0x992 0x0 0x0 0x0 0x0
					0x0 0x0 0xc28 0xa6a 0xb83 0x9ef
					0x8df 0x7bb 0xa3f 0x90d 0xad4 0x992
					0x0 0x0 0x0 0x0 0x0 0x0
					0xb49 0x9e0 0xab4 0x97a 0x906 0x7f8
					0x9d7 0x8d1 0xa6c 0x944 0x0 0x0
					0x0 0x0>;
				qcom,cpr-open-loop-voltage-fuse-adjustment = <0xc350 0x4e20 0x2710 0x2710 0xffffb1e0 0xc350
					0x4e20 0x2710 0x2710 0xffffb1e0 0xc350 0x4e20
					0x2710 0x2710 0xffffb1e0 0xfde8 0x4e20 0x61a8
					0x61a8 0xffffec78 0xfde8 0x4e20 0x61a8 0x61a8
					0xffffec78 0xfde8 0x4e20 0x61a8 0x61a8 0xffffec78
					0xfde8 0x4e20 0x61a8 0x61a8 0xffffec78 0xfde8
					0x4e20 0x61a8 0x61a8 0xffffec78 0xc350 0x4e20
					0x2710 0x2710 0xffffb1e0 0xc350 0x4e20 0x2710
					0x2710 0xffffb1e0 0xc350 0x4e20 0x2710 0x2710
					0xffffb1e0 0xfde8 0x4e20 0x61a8 0x61a8 0xffffec78
					0xfde8 0x4e20 0x61a8 0x61a8 0xffffec78 0xfde8
					0x4e20 0x61a8 0x61a8 0xffffec78 0xfde8 0x4e20
					0x61a8 0x61a8 0xffffec78 0xfde8 0x4e20 0x61a8
					0x61a8 0xffffec78 0x7530 0x0 0xffffd8f0 0xffffd8f0
					0xffff63c0 0x7530 0x0 0xffffd8f0 0xffffd8f0 0xffff63c0
					0x7530 0x0 0xffffd8f0 0xffffd8f0 0xffff63c0 0xafc8
					0x0 0x1388 0x1388 0xffff9e58 0xafc8 0x0
					0x1388 0x1388 0xffff9e58 0xafc8 0x0 0x1388
					0x1388 0xffff9e58 0xafc8 0x0 0x1388 0x1388
					0xffff9e58 0xafc8 0x0 0x1388 0x1388 0xffff9e58
					0x7530 0x0 0xffffd8f0 0xffffd8f0 0xffff63c0 0x7530
					0x0 0xffffd8f0 0xffffd8f0 0xffff63c0 0x7530 0x0
					0xffffd8f0 0xffffd8f0 0xffff63c0 0xafc8 0x0 0x1388
					0x1388 0xffff9e58 0xafc8 0x0 0x1388 0x1388
					0xffff9e58 0xafc8 0x0 0x1388 0x1388 0xffff9e58
					0xafc8 0x0 0x1388 0x1388 0xffff9e58 0xafc8
					0x0 0x1388 0x1388 0xffff9e58>;
				qcom,cpr-closed-loop-voltage-fuse-adjustment = <0x7530 0x61a8 0x4e20 0x4e20 0x4e20 0x7530
					0x61a8 0x0 0x4e20 0xffffc568 0x7530 0x61a8
					0x0 0x4e20 0xffffc568 0x7530 0x61a8 0x0
					0x4e20 0xffffc568 0x7530 0x61a8 0x0 0x4e20
					0xffffc568 0x7530 0x61a8 0x0 0x4e20 0xffffc568
					0x7530 0x61a8 0x0 0x4e20 0xffffc568 0x7530
					0x61a8 0x0 0x4e20 0xffffc568 0x7530 0x61a8
					0x4e20 0x4e20 0x4e20 0x7530 0x61a8 0x0
					0x4e20 0xffffc568 0x7530 0x61a8 0x0 0x4e20
					0xffffc568 0x7530 0x61a8 0x0 0x4e20 0xffffc568
					0x7530 0x61a8 0x0 0x4e20 0xffffc568 0x7530
					0x61a8 0x0 0x4e20 0xffffc568 0x7530 0x61a8
					0x0 0x4e20 0xffffc568 0x7530 0x61a8 0x0
					0x4e20 0xffffc568 0x2710 0x1388 0x0 0x0
					0x0 0x2710 0x1388 0xffffb1e0 0x0 0xffff7748
					0x2710 0x1388 0xffffb1e0 0x0 0xffff7748 0x2710
					0x1388 0xffffb1e0 0x0 0xffff7748 0x2710 0x1388
					0xffffb1e0 0x0 0xffff7748 0x2710 0x1388 0xffffb1e0
					0x0 0xffff7748 0x2710 0x1388 0xffffb1e0 0x0
					0xffff7748 0x2710 0x1388 0xffffb1e0 0x0 0xffff7748
					0x2710 0x1388 0x0 0x0 0x0 0x2710
					0x1388 0xffffb1e0 0x0 0xffff7748 0x2710 0x1388
					0xffffb1e0 0x0 0xffff7748 0x2710 0x1388 0xffffb1e0
					0x0 0xffff7748 0x2710 0x1388 0xffffb1e0 0x0
					0xffff7748 0x2710 0x1388 0xffffb1e0 0x0 0xffff7748
					0x2710 0x1388 0xffffb1e0 0x0 0xffff7748 0x2710
					0x1388 0xffffb1e0 0x0 0xffff7748>;
				qcom,allow-voltage-interpolation;
				qcom,allow-quotient-interpolation;
				qcom,cpr-scaled-open-loop-voltage-as-ceiling;
				qcom,cpr-aging-max-voltage-adjustment = <0x3a98>;
				qcom,cpr-aging-ref-corner = <0xd 0xd 0xd 0xd>;
				qcom,cpr-aging-ro-scaling-factor = <0xc80>;
				qcom,allow-aging-voltage-adjustment = <0x0 0x0 0x0 0x1 0x1 0x1
					0x1 0x1 0x0 0x0 0x0 0x1
					0x1 0x1 0x1 0x1 0x0 0x0
					0x0 0x1 0x1 0x1 0x1 0x1
					0x0 0x0 0x0 0x1 0x1 0x1
					0x1 0x1>;
			};
		};
		sony_cpr_thread1: thread@1 {
			qcom,cpr-thread-id = <0x1>;
			qcom,cpr-consecutive-up = <0x0>;
			qcom,cpr-consecutive-down = <0x3>;
			qcom,cpr-up-threshold = <0x2>;
			qcom,cpr-down-threshold = <0x2>;
			apc1_vreg: regulator {
				regulator-name = "apc1_corner";
				regulator-min-microvolt = <0x1>;
				regulator-max-microvolt = <0x19>;
				qcom,cpr-pd-bypass-mask = <0xe0>;
				qcom,cpr-fuse-corners = <0x5>;
				qcom,cpr-fuse-combos = <0x20>;
				qcom,cpr-speed-bins = <0x4>;
				qcom,cpr-speed-bin-corners = <0x19 0x15 0x19 0x19>;
				qcom,cpr-corners = <0x19 0x19 0x19 0x19 0x19 0x19
					0x19 0x19 0x15 0x15 0x15 0x15
					0x15 0x15 0x15 0x15 0x19 0x19
					0x19 0x19 0x19 0x19 0x19 0x19
					0x19 0x19 0x19 0x19 0x19 0x19
					0x19 0x19>;
				qcom,ldo-min-headroom-voltage = <0x249f0>;
				qcom,ldo-max-headroom-voltage = <0x72bf0>;
				qcom,ldo-max-voltage = <0xd9490>;
				qcom,uses-mem-acc;
				qcom,cpr-corner-fmax-map = <0x1 0x4 0x9 0xd 0x19 0x1
					0x4 0x9 0xd 0x15 0x1 0x4
					0x9 0xd 0x19 0x1 0x4 0x9
					0xd 0x19>;
				qcom,cpr-voltage-ceiling = <0xa3930 0xa3930 0xa3930 0xa3930 0xb5e28 0xb5e28
					0xb5e28 0xb5e28 0xb5e28 0xdcf28 0xdcf28 0xdcf28
					0xdcf28 0x116520 0x116520 0x116520 0x116520 0x116520
					0x116520 0x116520 0x116520 0x116520 0x116520 0x116520
					0x116520 0xa3930 0xa3930 0xa3930 0xa3930 0xb5e28
					0xb5e28 0xb5e28 0xb5e28 0xb5e28 0xdcf28 0xdcf28
					0xdcf28 0xdcf28 0x116520 0x116520 0x116520 0x116520
					0x116520 0x116520 0x116520 0x116520 0xa3930 0xa3930
					0xa3930 0xa3930 0xb5e28 0xb5e28 0xb5e28 0xb5e28
					0xb5e28 0xdcf28 0xdcf28 0xdcf28 0xdcf28 0x116520
					0x116520 0x116520 0x116520 0x116520 0x116520 0x116520
					0x116520 0x116520 0x116520 0x116520 0x116520 0xa3930
					0xa3930 0xa3930 0xa3930 0xb5e28 0xb5e28 0xb5e28
					0xb5e28 0xb5e28 0xdcf28 0xdcf28 0xdcf28 0xdcf28
					0x116520 0x116520 0x116520 0x116520 0x116520 0x116520
					0x116520 0x116520 0x116520 0x116520 0x116520 0x116520>;
				qcom,cpr-voltage-floor = <0x98968 0x98968 0x98968 0x98968 0x98968 0x98968
					0x98968 0x98968 0x98968 0x98968 0x98968 0x98968
					0x98968 0x98968 0x98968 0x98968 0x98968 0x98968
					0x98968 0x98968 0x98968 0x98968 0x98968 0x98968
					0x98968 0x98968 0x98968 0x98968 0x98968 0x98968
					0x98968 0x98968 0x98968 0x98968 0x98968 0x98968
					0x98968 0x98968 0x98968 0x98968 0x98968 0x98968
					0x98968 0x98968 0x98968 0x98968 0x98968 0x98968
					0x98968 0x98968 0x98968 0x98968 0x98968 0x98968
					0x98968 0x98968 0x98968 0x98968 0x98968 0x98968
					0x98968 0x98968 0x98968 0x98968 0x98968 0x98968
					0x98968 0x98968 0x98968 0x98968 0x98968 0x98968
					0x98968 0x98968 0x98968 0x98968 0x98968 0x98968
					0x98968 0x98968 0x98968 0x98968 0x98968 0x98968
					0x98968 0x98968 0x98968 0x98968 0x98968 0x98968
					0x98968 0x98968 0x98968 0x98968 0x98968 0x98968
					0x98968 0x98968 0x98968 0x98968 0x98968 0x98968
					0x98968 0x98968 0x98968 0x98968 0x98968 0x98968
					0x98968 0x98968 0x98968 0x98968 0x98968 0x98968
					0x98968 0x98968 0x98968 0x98968 0x98968 0x98968
					0x98968 0x98968 0x98968 0x98968 0x98968 0x98968
					0x98968 0x98968 0x98968 0x98968 0x98968 0x98968
					0x98968 0x98968 0x98968 0x98968 0x98968 0x98968
					0x98968 0x98968 0x98968 0x98968 0x98968 0x98968
					0x98968 0x98968 0x98968 0x98968 0x98968 0x98968
					0x72bf0 0x72bf0 0x72bf0 0x72bf0 0x72bf0 0x72bf0
					0x72bf0 0x72bf0 0x72bf0 0x72bf0 0x72bf0 0x72bf0
					0x72bf0 0x72bf0 0x72bf0 0x72bf0 0x72bf0 0x72bf0
					0x72bf0 0x72bf0 0x72bf0 0x72bf0 0x72bf0 0x72bf0
					0x72bf0 0x72bf0 0x72bf0 0x72bf0 0x72bf0 0x72bf0
					0x72bf0 0x72bf0 0x72bf0 0x72bf0 0x72bf0 0x72bf0
					0x72bf0 0x72bf0 0x72bf0 0x72bf0 0x72bf0 0x72bf0
					0x72bf0 0x72bf0 0x72bf0 0x72bf0 0x72bf0 0x72bf0
					0x72bf0 0x72bf0 0x98968 0x98968 0x98968 0x98968
					0x98968 0x98968 0x98968 0x98968 0x98968 0x98968
					0x98968 0x98968 0x98968 0x98968 0x98968 0x98968
					0x98968 0x98968 0x98968 0x98968 0x98968 0x98968
					0x98968 0x98968 0x98968 0x98968 0x98968 0x98968
					0x98968 0x98968 0x98968 0x98968 0x98968 0x98968
					0x98968 0x98968 0x98968 0x98968 0x98968 0x98968
					0x98968 0x98968 0x98968 0x98968 0x98968 0x98968
					0x98968 0x98968 0x98968 0x98968 0x98968 0x98968
					0x98968 0x98968 0x98968 0x98968 0x98968 0x98968
					0x98968 0x98968 0x98968 0x98968 0x98968 0x98968
					0x98968 0x98968 0x98968 0x98968 0x98968 0x98968
					0x98968 0x98968 0x98968 0x98968 0x98968 0x98968
					0x98968 0x98968 0x98968 0x98968 0x98968 0x98968
					0x98968 0x98968 0x98968 0x98968 0x98968 0x98968
					0x98968 0x98968 0x98968 0x98968 0x98968 0x98968
					0x98968 0x98968 0x98968 0x98968 0x98968 0x98968
					0x98968 0x98968 0x98968 0x98968 0x98968 0x98968
					0x98968 0x98968 0x98968 0x98968 0x98968 0x98968
					0x98968 0x98968 0x98968 0x98968 0x98968 0x98968
					0x98968 0x98968 0x98968 0x98968 0x98968 0x98968
					0x98968 0x98968 0x72bf0 0x72bf0 0x72bf0 0x72bf0
					0x72bf0 0x72bf0 0x72bf0 0x72bf0 0x72bf0 0x72bf0
					0x72bf0 0x72bf0 0x72bf0 0x72bf0 0x72bf0 0x72bf0
					0x72bf0 0x72bf0 0x72bf0 0x72bf0 0x72bf0 0x72bf0
					0x72bf0 0x72bf0 0x72bf0 0x72bf0 0x72bf0 0x72bf0
					0x72bf0 0x72bf0 0x72bf0 0x72bf0 0x72bf0 0x72bf0
					0x72bf0 0x72bf0 0x72bf0 0x72bf0 0x72bf0 0x72bf0
					0x72bf0 0x72bf0 0x98968 0x98968 0x98968 0x98968
					0x98968 0x98968 0x98968 0x98968 0x98968 0x98968
					0x98968 0x98968 0x98968 0x98968 0x98968 0x98968
					0x98968 0x98968 0x98968 0x98968 0x98968 0x98968
					0x98968 0x98968 0x98968 0x98968 0x98968 0x98968
					0x98968 0x98968 0x98968 0x98968 0x98968 0x98968
					0x98968 0x98968 0x98968 0x98968 0x98968 0x98968
					0x98968 0x98968 0x98968 0x98968 0x98968 0x98968
					0x98968 0x98968 0x98968 0x98968 0x98968 0x98968
					0x98968 0x98968 0x98968 0x98968 0x98968 0x98968
					0x98968 0x98968 0x98968 0x98968 0x98968 0x98968
					0x98968 0x98968 0x98968 0x98968 0x98968 0x98968
					0x98968 0x98968 0x98968 0x98968 0x98968 0x98968
					0x98968 0x98968 0x98968 0x98968 0x98968 0x98968
					0x98968 0x98968 0x98968 0x98968 0x98968 0x98968
					0x98968 0x98968 0x98968 0x98968 0x98968 0x98968
					0x98968 0x98968 0x98968 0x98968 0x98968 0x98968
					0x98968 0x98968 0x98968 0x98968 0x98968 0x98968
					0x98968 0x98968 0x98968 0x98968 0x98968 0x98968
					0x98968 0x98968 0x98968 0x98968 0x98968 0x98968
					0x98968 0x98968 0x98968 0x98968 0x98968 0x98968
					0x98968 0x98968 0x98968 0x98968 0x98968 0x98968
					0x98968 0x98968 0x98968 0x98968 0x98968 0x98968
					0x98968 0x98968 0x98968 0x98968 0x98968 0x98968
					0x98968 0x98968 0x98968 0x98968 0x98968 0x98968
					0x98968 0x98968 0x72bf0 0x72bf0 0x72bf0 0x72bf0
					0x72bf0 0x72bf0 0x72bf0 0x72bf0 0x72bf0 0x72bf0
					0x72bf0 0x72bf0 0x72bf0 0x72bf0 0x72bf0 0x72bf0
					0x72bf0 0x72bf0 0x72bf0 0x72bf0 0x72bf0 0x72bf0
					0x72bf0 0x72bf0 0x72bf0 0x72bf0 0x72bf0 0x72bf0
					0x72bf0 0x72bf0 0x72bf0 0x72bf0 0x72bf0 0x72bf0
					0x72bf0 0x72bf0 0x72bf0 0x72bf0 0x72bf0 0x72bf0
					0x72bf0 0x72bf0 0x72bf0 0x72bf0 0x72bf0 0x72bf0
					0x72bf0 0x72bf0 0x72bf0 0x72bf0 0x98968 0x98968
					0x98968 0x98968 0x98968 0x98968 0x98968 0x98968
					0x98968 0x98968 0x98968 0x98968 0x98968 0x98968
					0x98968 0x98968 0x98968 0x98968 0x98968 0x98968
					0x98968 0x98968 0x98968 0x98968 0x98968 0x98968
					0x98968 0x98968 0x98968 0x98968 0x98968 0x98968
					0x98968 0x98968 0x98968 0x98968 0x98968 0x98968
					0x98968 0x98968 0x98968 0x98968 0x98968 0x98968
					0x98968 0x98968 0x98968 0x98968 0x98968 0x98968
					0x98968 0x98968 0x98968 0x98968 0x98968 0x98968
					0x98968 0x98968 0x98968 0x98968 0x98968 0x98968
					0x98968 0x98968 0x98968 0x98968 0x98968 0x98968
					0x98968 0x98968 0x98968 0x98968 0x98968 0x98968
					0x98968 0x98968 0x98968 0x98968 0x98968 0x98968
					0x98968 0x98968 0x98968 0x98968 0x98968 0x98968
					0x98968 0x98968 0x98968 0x98968 0x98968 0x98968
					0x98968 0x98968 0x98968 0x98968 0x98968 0x98968
					0x98968 0x98968 0x98968 0x98968 0x98968 0x98968
					0x98968 0x98968 0x98968 0x98968 0x98968 0x98968
					0x98968 0x98968 0x98968 0x98968 0x98968 0x98968
					0x98968 0x98968 0x98968 0x98968 0x98968 0x98968
					0x98968 0x98968 0x98968 0x98968 0x98968 0x98968
					0x98968 0x98968 0x98968 0x98968 0x98968 0x98968
					0x98968 0x98968 0x98968 0x98968 0x98968 0x98968
					0x98968 0x98968 0x98968 0x98968 0x98968 0x98968
					0x98968 0x98968 0x98968 0x98968 0x72bf0 0x72bf0
					0x72bf0 0x72bf0 0x72bf0 0x72bf0 0x72bf0 0x72bf0
					0x72bf0 0x72bf0 0x72bf0 0x72bf0 0x72bf0 0x72bf0
					0x72bf0 0x72bf0 0x72bf0 0x72bf0 0x72bf0 0x72bf0
					0x72bf0 0x72bf0 0x72bf0 0x72bf0 0x72bf0 0x72bf0
					0x72bf0 0x72bf0 0x72bf0 0x72bf0 0x72bf0 0x72bf0
					0x72bf0 0x72bf0 0x72bf0 0x72bf0 0x72bf0 0x72bf0
					0x72bf0 0x72bf0 0x72bf0 0x72bf0 0x72bf0 0x72bf0
					0x72bf0 0x72bf0 0x72bf0 0x72bf0 0x72bf0 0x72bf0>;
				qcom,cpr-floor-to-ceiling-max-range = <0xc350 0xc350 0xc350 0xc350 0x13880 0x13880
					0x13880 0x13880 0x13880 0x13880 0x13880 0x13880
					0x13880 0x13880 0x13880 0x13880 0x13880 0x13880
					0x13880 0x13880 0x13880 0x13880 0x13880 0x13880
					0x13880 0xc350 0xc350 0xc350 0xc350 0x13880
					0x13880 0x13880 0x13880 0x13880 0x13880 0x13880
					0x13880 0x13880 0x13880 0x13880 0x13880 0x13880
					0x13880 0x13880 0x13880 0x13880 0xc350 0xc350
					0xc350 0xc350 0x13880 0x13880 0x13880 0x13880
					0x13880 0x13880 0x13880 0x13880 0x13880 0x13880
					0x13880 0x13880 0x13880 0x13880 0x13880 0x13880
					0x13880 0x13880 0x13880 0x13880 0x13880 0xc350
					0xc350 0xc350 0xc350 0x13880 0x13880 0x13880
					0x13880 0x13880 0x13880 0x13880 0x13880 0x13880
					0x13880 0x13880 0x13880 0x13880 0x13880 0x13880
					0x13880 0x13880 0x13880 0x13880 0x13880 0x13880>;
				qcom,corner-frequencies = <0x124f8000 0x18085800 0x1c9c3800 0x21301800 0x26e8f000 0x2b7cd000
					0x3010b000 0x34a49000 0x38137800 0x3dcc5000 0x42603000 0x46f41000
					0x4a62f800 0x4ef6d800 0x538ab800 0x581e9800 0x5cb27800 0x61465800
					0x65da3800 0x6a6e1800 0x6cb80800 0x7270e000 0x7704c000 0x7b98a000
					0x802c8000 0x124f8000 0x18085800 0x1c9c3800 0x21301800 0x26e8f000
					0x2b7cd000 0x3010b000 0x34a49000 0x38137800 0x3dcc5000 0x42603000
					0x46f41000 0x4a62f800 0x4ef6d800 0x538ab800 0x581e9800 0x5cb27800
					0x61465800 0x65da3800 0x6a6e1800 0x6b931000 0x124f8000 0x18085800
					0x1c9c3800 0x21301800 0x26e8f000 0x2b7cd000 0x3010b000 0x34a49000
					0x38137800 0x3dcc5000 0x42603000 0x46f41000 0x4a62f800 0x4ef6d800
					0x538ab800 0x581e9800 0x5cb27800 0x61465800 0x65da3800 0x6a6e1800
					0x6cb80800 0x7270e000 0x7704c000 0x7b98a000 0x802c8000 0x124f8000
					0x18085800 0x1c9c3800 0x21301800 0x26e8f000 0x2b7cd000 0x3010b000
					0x34a49000 0x38137800 0x3dcc5000 0x42603000 0x46f41000 0x4a62f800
					0x4ef6d800 0x538ab800 0x581e9800 0x5cb27800 0x61465800 0x65da3800
					0x6a6e1800 0x6cb80800 0x7270e000 0x7704c000 0x7b98a000 0x802c8000>;
				qcom,cpr-ro-scaling-factor = <0x0 0x0 0xc28 0xa6a 0xb83 0x9ef
					0x8df 0x7bb 0xa3f 0x90d 0xad4 0x992
					0x0 0x0 0x0 0x0 0x0 0x0
					0xc28 0xa6a 0xb83 0x9ef 0x8df 0x7bb
					0xa3f 0x90d 0xad4 0x992 0x0 0x0
					0x0 0x0 0x0 0x0 0xc28 0xa6a
					0xb83 0x9ef 0x8df 0x7bb 0xa3f 0x90d
					0xad4 0x992 0x0 0x0 0x0 0x0
					0x0 0x0 0xc28 0xa6a 0xb83 0x9ef
					0x8df 0x7bb 0xa3f 0x90d 0xad4 0x992
					0x0 0x0 0x0 0x0 0x0 0x0
					0xb49 0x9e0 0xab4 0x97a 0x906 0x7f8
					0x9d7 0x8d1 0xa6c 0x944 0x0 0x0
					0x0 0x0>;
				qcom,cpr-open-loop-voltage-fuse-adjustment = <0x9c40 0x4e20 0x88b8 0xffff7748 0x4e20 0x9c40
					0x4e20 0x88b8 0xffff7748 0x4e20 0x9c40 0x4e20
					0x88b8 0x4e20 0x4e20 0xd6d8 0x4e20 0xc350
					0x88b8 0x88b8 0xd6d8 0x4e20 0xc350 0x88b8
					0x88b8 0xd6d8 0x4e20 0xc350 0x88b8 0x88b8
					0xd6d8 0x4e20 0xc350 0x88b8 0x88b8 0xd6d8
					0x4e20 0xc350 0x88b8 0x88b8 0x9c40 0x4e20
					0x88b8 0xffff7748 0x4e20 0x9c40 0x4e20 0x88b8
					0xffff7748 0x4e20 0x9c40 0x4e20 0x88b8 0x4e20
					0x4e20 0xd6d8 0x4e20 0xc350 0x88b8 0x88b8
					0xd6d8 0x4e20 0xc350 0x88b8 0x88b8 0xd6d8
					0x4e20 0xc350 0x88b8 0x88b8 0xd6d8 0x4e20
					0xc350 0x88b8 0x88b8 0xd6d8 0x4e20 0xc350
					0x88b8 0x88b8 0x4e20 0x0 0x3a98 0xffff2928
					0x0 0x4e20 0x0 0x3a98 0xffff2928 0x0
					0x4e20 0x0 0x3a98 0x0 0x0 0x88b8
					0x0 0x7530 0x3a98 0x3a98 0x88b8 0x0
					0x7530 0x3a98 0x3a98 0x88b8 0x0 0x7530
					0x3a98 0x3a98 0x88b8 0x0 0x7530 0x3a98
					0x3a98 0x88b8 0x0 0x7530 0x3a98 0x3a98
					0x4e20 0x0 0x3a98 0xffff2928 0x0 0x4e20
					0x0 0x3a98 0xffff2928 0x0 0x4e20 0x0
					0x3a98 0x0 0x0 0x88b8 0x0 0x7530
					0x3a98 0x3a98 0x88b8 0x0 0x7530 0x3a98
					0x3a98 0x88b8 0x0 0x7530 0x3a98 0x3a98
					0x88b8 0x0 0x7530 0x3a98 0x3a98 0x88b8
					0x0 0x7530 0x3a98 0x3a98>;
				qcom,cpr-closed-loop-voltage-fuse-adjustment = <0xd6d8 0xd6d8 0xea60 0xffffd8f0 0xea60 0x4e20
					0x4e20 0x4e20 0xffff3cb0 0x4e20 0x4e20 0x4e20
					0x4e20 0x4e20 0x4e20 0x4e20 0x4e20 0x4e20
					0x4e20 0x4e20 0x4e20 0x4e20 0x4e20 0x4e20
					0x4e20 0x4e20 0x4e20 0x4e20 0x4e20 0x4e20
					0x4e20 0x4e20 0x4e20 0x4e20 0x4e20 0x4e20
					0x4e20 0x4e20 0x4e20 0x4e20 0xd6d8 0xd6d8
					0xea60 0xffffd8f0 0xea60 0x4e20 0x4e20 0x4e20
					0xffff3cb0 0x4e20 0x4e20 0x4e20 0x4e20 0x4e20
					0x4e20 0x4e20 0x4e20 0x4e20 0x4e20 0x4e20
					0x4e20 0x4e20 0x4e20 0x4e20 0x4e20 0x4e20
					0x4e20 0x4e20 0x4e20 0x4e20 0x4e20 0x4e20
					0x4e20 0x4e20 0x4e20 0x4e20 0x4e20 0x4e20
					0x4e20 0x4e20 0x88b8 0x88b8 0x9c40 0xffff8ad0
					0x9c40 0x0 0x0 0x0 0xfffeee90 0x0
					0x0 0x0 0x0 0x0 0x0 0x0
					0x0 0x0 0x0 0x0 0x0 0x0
					0x0 0x0 0x0 0x0 0x0 0x0
					0x0 0x0 0x0 0x0 0x0 0x0
					0x0 0x0 0x0 0x0 0x0 0x0
					0x88b8 0x88b8 0x9c40 0xffff8ad0 0x9c40 0x0
					0x0 0x0 0xfffeee90 0x0 0x0 0x0
					0x0 0x0 0x0 0x0 0x0 0x0
					0x0 0x0 0x0 0x0 0x0 0x0
					0x0 0x0 0x0 0x0 0x0 0x0
					0x0 0x0 0x0 0x0 0x0 0x0
					0x0 0x0 0x0 0x0>;
				qcom,cpr-open-loop-voltage-adjustment = <0xffffc568 0xffffc568 0xffffc568 0xffffc568 0xffffd508 0xffffd120
					0xffffcd38 0xffffc950 0xffffc568 0xffffb9b0 0xffffadf8 0xffffa628
					0xffff9e58 0xffff9e58 0xffff9a70 0xffff9a70 0xffff9688 0xffff9688
					0xffff92a0 0xffff92a0 0xffff92a0 0xffff8eb8 0xffff8eb8 0xffff8ad0
					0xffff8ad0 0xffffc568 0xffffc568 0xffffc568 0xffffc568 0xffffd508
					0xffffd120 0xffffcd38 0xffffc950 0xffffc568 0xffffb9b0 0xffffadf8
					0xffffa628 0xffff9e58 0xffff9e58 0xffff9a70 0xffff9a70 0xffff9688
					0xffff9688 0xffff92a0 0xffff92a0 0xffff92a0 0xffffc568 0xffffc568
					0xffffc568 0xffffc568 0xffffd508 0xffffd120 0xffffcd38 0xffffc950
					0xffffc568 0xffffb9b0 0xffffadf8 0xffffa628 0xffff9e58 0xffff9e58
					0xffff9a70 0xffff9a70 0xffff9688 0xffff9688 0xffff92a0 0xffff92a0
					0xffff92a0 0xffff8eb8 0xffff8eb8 0xffff8ad0 0xffff8ad0 0xffffc568
					0xffffc568 0xffffc568 0xffffc568 0xffffd508 0xffffd120 0xffffcd38
					0xffffc950 0xffffc568 0xffffb9b0 0xffffadf8 0xffffa628 0xffff9e58
					0xffff9e58 0xffff9a70 0xffff9a70 0xffff9688 0xffff9688 0xffff92a0
					0xffff92a0 0xffff92a0 0xffff8eb8 0xffff8eb8 0xffff8ad0 0xffff8ad0>;
				qcom,cpr-open-loop-voltage-min-diff = <0x0 0x0 0x0 0x0 0xffff3cb0 0x0
					0x0 0x0 0x0 0x0 0x0 0x0
					0x0 0x0 0x0 0x0 0x0 0x0
					0x0 0x0 0x0 0x0 0x0 0x0
					0x0 0x0 0x0 0x0 0x0 0xffff3cb0
					0x0 0x0 0x0 0x0 0x0 0x0
					0x0 0x0 0x0 0x0 0x0 0x0
					0x0 0x0 0x0 0x0 0x0 0x0
					0x0 0x0 0xffff3cb0 0x0 0x0 0x0
					0x0 0x0 0x0 0x0 0x0 0x0
					0x0 0x0 0x0 0x0 0x0 0x0
					0x0 0x0 0x0 0x0 0x0 0x0
					0x0 0x0 0x0 0xffff3cb0 0x0 0x0
					0x0 0x0 0x0 0x0 0x0 0x0
					0x0 0x0 0x0 0x0 0x0 0x0
					0x0 0x0 0x0 0x0 0x0 0x0>;
				qcom,cpr-closed-loop-voltage-adjustment = <0xffffc568 0xffffc568 0xffffc568 0xffffc568 0xffffd508 0xffffd120
					0xffffcd38 0xffffc950 0xffffc568 0xffffb9b0 0xffffadf8 0xffffa628
					0xffff9e58 0xffff9e58 0xffff9a70 0xffff9a70 0xffff9688 0xffff9688
					0xffff92a0 0xffff92a0 0xffff92a0 0xffff8eb8 0xffff8eb8 0xffff8ad0
					0xffff8ad0 0xffffc568 0xffffc568 0xffffc568 0xffffc568 0xffffd508
					0xffffd120 0xffffcd38 0xffffc950 0xffffc568 0xffffb9b0 0xffffadf8
					0xffffa628 0xffff9e58 0xffff9e58 0xffff9a70 0xffff9a70 0xffff9688
					0xffff9688 0xffff92a0 0xffff92a0 0xffff92a0 0xffffc568 0xffffc568
					0xffffc568 0xffffc568 0xffffd508 0xffffd120 0xffffcd38 0xffffc950
					0xffffc568 0xffffb9b0 0xffffadf8 0xffffa628 0xffff9e58 0xffff9e58
					0xffff9a70 0xffff9a70 0xffff9688 0xffff9688 0xffff92a0 0xffff92a0
					0xffff92a0 0xffff8eb8 0xffff8eb8 0xffff8ad0 0xffff8ad0 0xffffc568
					0xffffc568 0xffffc568 0xffffc568 0xffffd508 0xffffd120 0xffffcd38
					0xffffc950 0xffffc568 0xffffb9b0 0xffffadf8 0xffffa628 0xffff9e58
					0xffff9e58 0xffff9a70 0xffff9a70 0xffff9688 0xffff9688 0xffff92a0
					0xffff92a0 0xffff92a0 0xffff8eb8 0xffff8eb8 0xffff8ad0 0xffff8ad0>;
				qcom,allow-voltage-interpolation;
				qcom,allow-quotient-interpolation;
				qcom,cpr-scaled-open-loop-voltage-as-ceiling;
				qcom,cpr-aging-max-voltage-adjustment = <0x3a98>;
				qcom,cpr-aging-ref-corner = <0xd 0xd 0xd 0xd>;
				qcom,cpr-aging-ro-scaling-factor = <0xc80>;
				qcom,allow-aging-voltage-adjustment = <0x0 0x0 0x0 0x1 0x1 0x1
					0x1 0x1 0x0 0x0 0x0 0x1
					0x1 0x1 0x1 0x1 0x0 0x0
					0x0 0x1 0x1 0x1 0x1 0x1
					0x0 0x0 0x0 0x1 0x1 0x1
					0x1 0x1>;
				qcom,cpr-dynamic-floor-corner = <0x1>;
			};
		};
	};
	sony_apc0_mem_acc: apc0-pwrcl-mem-acc-regulator {
		status = "disabled";
		compatible = "qcom,mem-acc-regulator";
		reg = <0x99e00c0 0x4>;
		reg-names = "acc-sel-l1";
		regulator-name = "apc0_pwrcl_mem_acc_corner";
		regulator-min-microvolt = <0x1>;
		regulator-max-microvolt = <0x2>;
		qcom,corner-acc-map = <0x2 0x0>;
		qcom,acc-sel-l1-bit-pos = <0x0>;
		qcom,acc-sel-l1-bit-size = <0x2>;
	};
	sony_apc1_mem_acc: apc1-perfcl-mem-acc-regulator {
		status = "disabled";
		compatible = "qcom,mem-acc-regulator";
		reg = <0x99e00c0 0x4>;
		reg-names = "acc-sel-l1";
		regulator-name = "apc1_perfcl_mem_acc_corner";
		regulator-min-microvolt = <0x1>;
		regulator-max-microvolt = <0x2>;
		qcom,corner-acc-map = <0x2 0x0>;
		qcom,acc-sel-l1-bit-pos = <0x2>;
		qcom,acc-sel-l1-bit-size = <0x2>;
	};
	sony_apcc_mem_acc: apcc-l3-mem-acc-regulator {
		status = "disabled";
		compatible = "qcom,mem-acc-regulator";
		reg = <0x99e00c0 0x4>;
		reg-names = "acc-sel-l1";
		regulator-name = "apcc_l3_mem_acc_corner";
		regulator-min-microvolt = <0x1>;
		regulator-max-microvolt = <0x2>;
		qcom,corner-acc-map = <0x1 0x0>;
		qcom,acc-sel-l1-bit-pos = <0x4>;
		qcom,acc-sel-l1-bit-size = <0x1>;
	};
	sony_kryo0: regulator@99a2000 {
		status = "disabled";
		compatible = "qcom,kryo-regulator";
		regulator-name = "kryo0";
		reg = <0x99a2000 0x1000 0x99e0000 0x1000 0x9820000 0x1000>;
		reg-names = "pm-apc", "pm-apcc", "apcs-csr";
		regulator-min-microvolt = <0x724e5>;
		regulator-max-microvolt = <0xd9e33>;
		qcom,ldo-default-voltage = <0xb71b0>;
		qcom,retention-voltage = <0x7ef40>;
		qcom,ldo-headroom-voltage = <0x249f0>;
		qcom,vref-functional-step-voltage = <0x1172>;
		qcom,vref-functional-min-voltage = <0x4f6a5>;
		qcom,vref-retention-step-voltage = <0x1172>;
		qcom,vref-retention-min-voltage = <0x4f6a5>;
		qcom,ldo-config-init = <0xf1f0e471>;
		qcom,apm-config-init = <0x0>;
		qcom,cluster-num = <0x0>;
		sony_kryo0_retention: regulator {
			regulator-name = "kryo0-retention";
			regulator-min-microvolt = <0x724e5>;
			regulator-max-microvolt = <0xd9e33>;
		};
	};
	sony_kryo1: regulator@99d2000 {
		status = "disabled";
		compatible = "qcom,kryo-regulator";
		regulator-name = "kryo1";
		reg = <0x99d2000 0x1000 0x99e0000 0x1000 0x9820000 0x1000>;
		reg-names = "pm-apc", "pm-apcc", "apcs-csr";
		regulator-min-microvolt = <0x724e5>;
		regulator-max-microvolt = <0xd9e33>;
		qcom,ldo-default-voltage = <0xb71b0>;
		qcom,retention-voltage = <0x7ef40>;
		qcom,ldo-headroom-voltage = <0x249f0>;
		qcom,vref-functional-step-voltage = <0x1172>;
		qcom,vref-functional-min-voltage = <0x4f6a5>;
		qcom,vref-retention-step-voltage = <0x1172>;
		qcom,vref-retention-min-voltage = <0x4f6a5>;
		qcom,cluster-num = <0x1>;
		qcom,ldo-config-init = <0xf1f0e471>;
		qcom,apm-config-init = <0x0>;
		sony_kryo1_retention: regulator {
			regulator-name = "kryo1-retention";
			regulator-min-microvolt = <0x724e5>;
			regulator-max-microvolt = <0xd9e33>;
		};
	};
	sony_apcc_spm: qcom,spm@9a10000 {
		status = "disabled";
		compatible = "qcom,spm-v2";
		#address-cells = <0x1>;
		#size-cells = <0x1>;
		reg = <0x9a10000 0x1000>;
		qcom,name = "system-cbf";
		qcom,saw2-ver-reg = <0xfd0>;
		qcom,cpu-vctl-list = <&CPU0 &CPU1 &CPU2 &CPU3>;
		qcom,vctl-timeout-us = <0x1f4>;
		qcom,vctl-port = <0x0>;
		qcom,phase-port = <0x1>;
		qcom,saw2-avs-ctl = <0x1100>;
		qcom,pfm-port = <0x2>;
	};
};

&{/soc/qcom,spmi@400f000/pmic@1} {
	sony_pm8994_s11: spm-regulator@3200 {
		status = "disabled";
		compatible = "qcom,spm-regulator";
		reg = <0x3200>;
		regulator-name = "pm8994_s11";
		regulator-min-microvolt = <0x73f78>;
		regulator-max-microvolt = <0x116520>;
		qcom,max-voltage-step = <0x249f0>;
		qcom,cpu-num = <0x0>;
		qcom,recal-mask = <0x3>;
		sony_pm8994_s11_limit: avs-limit-regulator {
			regulator-name = "pm8994_s11_avs_limit";
			regulator-min-microvolt = <0x73f78>;
			regulator-max-microvolt = <0x116520>;
		};
	};
};

/* Sony VDD_APCC = S8+S9+S10+S11, S11 gang leader controlled via SPM.
 * The live native provider is RPM, not an absent direct-SPMI container.
 * Do not instantiate competing independent RPM clients for these phases.
 */
&pm8994_s8 { status = "disabled"; };
&pm8994_s9 { status = "disabled"; };
&pm8994_s10 { status = "disabled"; };
&pm8994_s11 { status = "disabled"; };
